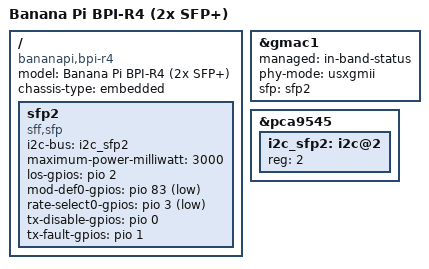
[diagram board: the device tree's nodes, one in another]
// SPDX-License-Identifier: GPL-2.0-only OR MIT

/dts-v1/;

#include "mt7988a-bananapi-bpi-r4.dtsi"

/ {
	compatible = "bananapi,bpi-r4", "mediatek,mt7988a";
	model = "Banana Pi BPI-R4 (2x SFP+)";
	chassis-type = "embedded";

	/* SFP2 cage (LAN) */
	sfp2: sfp2 {
		compatible = "sff,sfp";
		i2c-bus = <&i2c_sfp2>;
		maximum-power-milliwatt = <3000>;

		los-gpios = <&pio 2 GPIO_ACTIVE_HIGH>;
		mod-def0-gpios = <&pio 83 GPIO_ACTIVE_LOW>;
		rate-select0-gpios = <&pio 3 GPIO_ACTIVE_LOW>;
		tx-disable-gpios = <&pio 0 GPIO_ACTIVE_HIGH>;
		tx-fault-gpios = <&pio 1 GPIO_ACTIVE_HIGH>;
	};
};

&gmac1 {
	managed = "in-band-status";
	phy-mode = "usxgmii";
	sfp = <&sfp2>;
};

&pca9545 {
	i2c_sfp2: i2c@2 {
		#address-cells = <1>;
		#size-cells = <0>;
		reg = <2>;
	};
};
